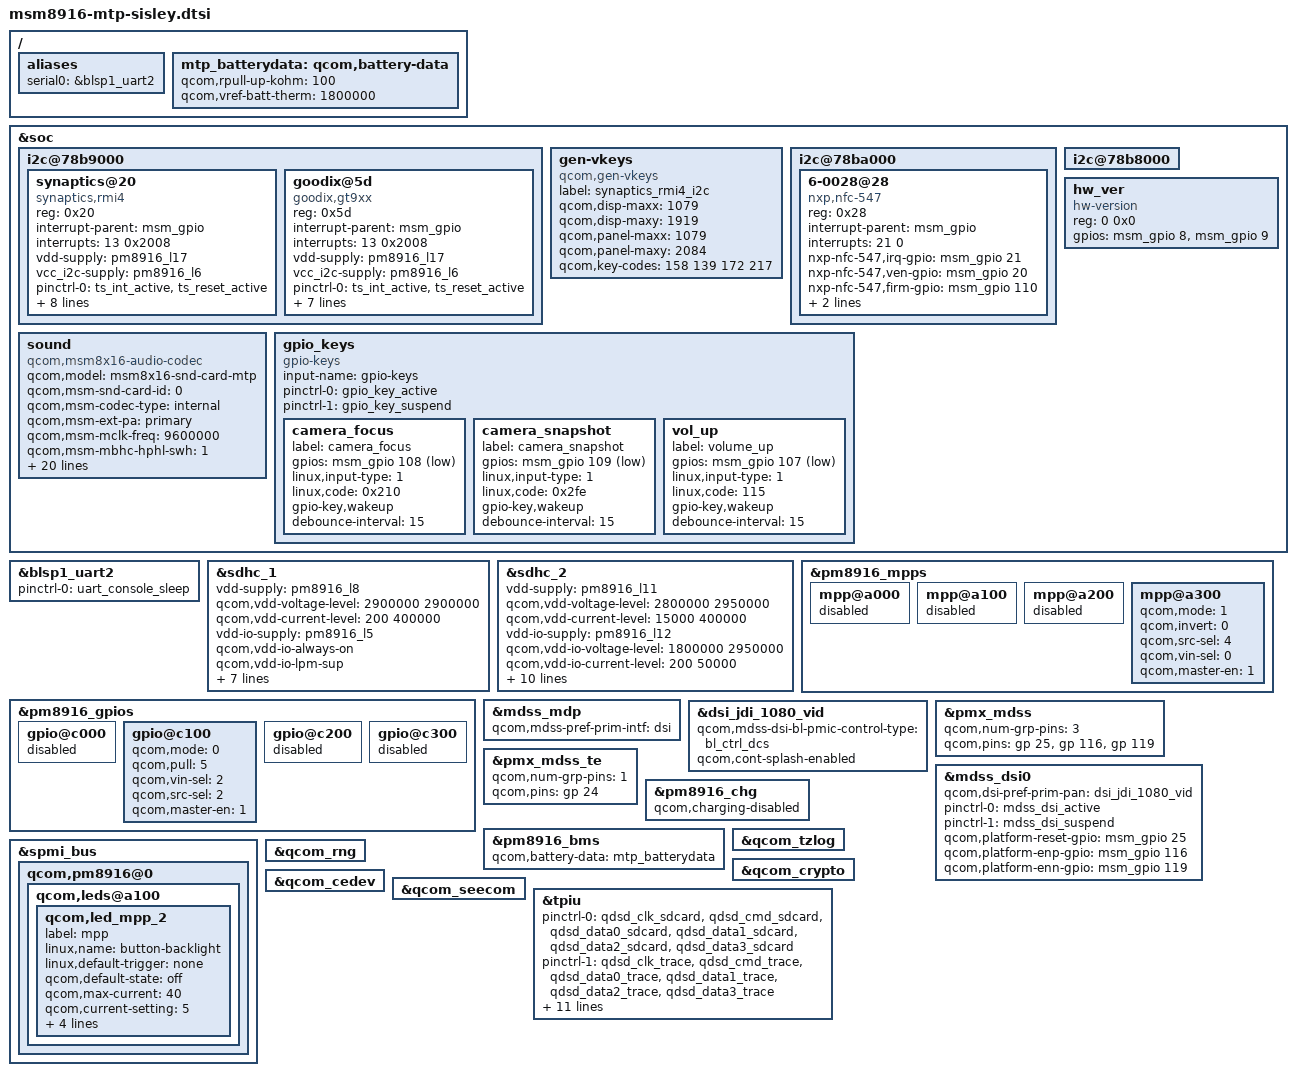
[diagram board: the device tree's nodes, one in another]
/* Copyright (c) 2014, The Linux Foundation. All rights reserved.
 *
 * This program is free software; you can redistribute it and/or modify
 * it under the terms of the GNU General Public License version 2 and
 * only version 2 as published by the Free Software Foundation.
 *
 * This program is distributed in the hope that it will be useful,
 * but WITHOUT ANY WARRANTY; without even the implied warranty of
 * MERCHANTABILITY or FITNESS FOR A PARTICULAR PURPOSE.  See the
 * GNU General Public License for more details.
 */

#include "msm8916.dtsi"
#include "msm8916-pinctrl.dtsi"
//chenglogn1 for sisley sub cam
#include "msm8916-camera-sensor-sisley.dtsi"//"msm8916-camera-sensor-mtp.dtsi"

/ {
	aliases {
		serial0 = &blsp1_uart2;
	};
};

&soc {
	i2c@78b9000 { /* BLSP1 QUP5 */
		synaptics@20 {
			compatible = "synaptics,rmi4";
			reg = <0x20>;
			interrupt-parent = <&msm_gpio>;
			interrupts = <13 0x2008>;
			vdd-supply = <&pm8916_l17>;
			vcc_i2c-supply = <&pm8916_l6>;
			/* pins used by touchscreen */
			pinctrl-names = "pmx_ts_active","pmx_ts_suspend";
			pinctrl-0 = <&ts_int_active &ts_reset_active>;
			pinctrl-1 = <&ts_int_suspend &ts_reset_suspend>;
			synaptics,irq-gpio = <&msm_gpio 13 0x2008>;
			synaptics,reset-gpio = <&msm_gpio 12 0x0>;
			synaptics,display-coords = <0 0 1079 1919>;
			synaptics,panel-coords = <0 0 1079 2084>;
			synaptics,i2c-pull-up;
			synaptics,power-down;
			synaptics,disable-gpios;
		};
		goodix@5d {
			compatible = "goodix,gt9xx";
			reg = <0x5d>;
			interrupt-parent = <&msm_gpio>;
			interrupts = <13 0x2008>;
			vdd-supply = <&pm8916_l17>;
			vcc_i2c-supply = <&pm8916_l6>;
			/* pins used by touchscreen */
			pinctrl-names = "pmx_ts_active","pmx_ts_suspend";
			pinctrl-0 = <&ts_int_active &ts_reset_active>;
			pinctrl-1 = <&ts_int_suspend &ts_reset_suspend>;
			goodix,reset-gpio = <&msm_gpio 12 0x0>;
			goodix,irq-gpio = <&msm_gpio 13 0x2008>;
			//goodix,ldo-en-gpio = <&msmgpio 15 0x00>;
			goodix,panel-coords = <0 0 720 1280>;
			goodix,display-coords = <0 0 720 1280>;
			goodix,button-map= <158 102 139>;
			goodix,family-id = <0x0>;
			/*
			goodix,cfg-data = [
		41 1C 02 C0 03 05 31 07 03 08
		14 08 41 32 03 04 00 00 00 00
		00 00 00 18 1A 1E 14 8B 2B 0C
		1C 1E 8C 20 00 00 00 9A 03 2D
		00 00 00 00 00 00 00 00 00 22
		00 4B FA 94 85 02 05 00 00 E5
		1B 1A ED 1C 1C 3C 1F 1E 3C 1F
		24 08 27 1F 00 00 10 38 58 00
		67 60 45 FF FF 07 00 00 00 00
		00 01 06 14 0C 16 E8 03 02 00
		00 03 28 28 E5 00 23 23 00 00
		00 00 02 04 06 08 0A 0C 0E 10
		12 14 16 18 FF FF FF FF FF FF
		FF FF FF FF FF FF FF FF FF FF
		FF FF 00 02 04 06 08 0A 0C 0F
		10 12 13 16 18 1C 1D 1E 1F 20
		21 22 24 26 FF FF FF FF FF FF
		FF FF FF FF FF FF FF FF FF FF
		FF FF FF FF 90 01];
		*/
		};
	};

	gen-vkeys {
		compatible = "qcom,gen-vkeys";
		label = "synaptics_rmi4_i2c";
		qcom,disp-maxx = <1079>;
		qcom,disp-maxy = <1919>;
		qcom,panel-maxx = <1079>;
		qcom,panel-maxy = <2084>;
		qcom,key-codes = <158 139 172 217>;
	};

	i2c@78ba000 { /* BLSP1 QUP6 */
		6-0028@28 {
			compatible = "nxp,nfc-547";
			reg = <0x28>;
          /*
			qcom,irq-gpio = <&msm_gpio 21 0x00>;
			qcom,dis-gpio = <&msm_gpio 20 0x00>;
			qcom,clk-src = "BBCLK2";
			qcom,clk-en-gpio = <&msm_gpio 0 0x00>;
          */
			interrupt-parent = <&msm_gpio>;
			interrupts = <21 0>;
          /*
			interrupt-names = "nfc_irq";
			pinctrl-names = "nfc_active","nfc_suspend";
			pinctrl-0 = <&nfc_int_active &nfc_disable_active>;
			pinctrl-1 = <&nfc_int_suspend &nfc_disable_suspend>;
			*/
			nxp-nfc-547,irq-gpio = <&msm_gpio 21 0x00>;
			nxp-nfc-547,ven-gpio = <&msm_gpio 20 0x00>;
			nxp-nfc-547,firm-gpio = <&msm_gpio 110 0x00>;
			qcom,clk-gpio = <&pm8916_gpios 2 0>;
			clocks = <&clock_rpm clk_bb_clk2_pin>;
			clock-names = "nfc_clk";
		};
	};

	i2c@78b8000 { /* BLSP1 QUP4 */

	};

	sound {
		compatible = "qcom,msm8x16-audio-codec";
		qcom,model = "msm8x16-snd-card-mtp";
		qcom,msm-snd-card-id = <0>;
		qcom,msm-codec-type = "internal";
		qcom,msm-ext-pa = "primary";
		qcom,msm-mclk-freq = <9600000>;
		qcom,msm-mbhc-hphl-swh = <1>;
		qcom,msm-mbhc-gnd-swh = <0>;
		/* lenovo-sw, lily8, 2014-09-11,for micbias-ext-cap-mode from QC patch,  begin*/
		qcom,msm-micbias1-ext-cap;
		/* lenovo-sw, lily8, 2014-09-11,for micbias-ext-cap-mode from QC patch,  end*/
		qcom,msm-hs-micbias-type = "internal";
		qcom,audio-routing =
			"RX_BIAS", "MCLK",
			"SPK_RX_BIAS", "MCLK",
			"INT_LDO_H", "MCLK",
			"MIC BIAS External", "Handset Mic",
			"MIC BIAS Internal2", "Headset Mic",
			"MIC BIAS External", "Secondary Mic",
			"AMIC1", "MIC BIAS External",
			"AMIC2", "MIC BIAS Internal2",
			"AMIC3", "MIC BIAS External";
		qcom,ext-spk-amp-gpio-1 = <&msm_gpio 97 0x0>;
		qcom,ext-spk-amp-gpio-2 = <&msm_gpio 98 0x0>;
		pinctrl-names = "cdc_lines_act",
				"cdc_lines_sus",
				"cdc_lines_sec_ext_act",
				"cdc_lines_sec_ext_sus",
				"cross_conn_det_act",
				"cross_conn_det_sus";
		pinctrl-0 = <&cdc_pdm_lines_act>;
		pinctrl-1 = <&cdc_pdm_lines_sus>;
		pinctrl-2 = <&cdc_pdm_lines_act &cdc_ext_pa_act
						&cdc_ext_pa_ws_act>;
		pinctrl-3 = <&cdc_pdm_lines_sus &cdc_ext_pa_sus
						&cdc_ext_pa_ws_sus>;
		pinctrl-4 = <&cross_conn_det_act>;
		pinctrl-5 = <&cross_conn_det_sus>;
	};
	/*lenovo-sw jixj 2014.6.9 add begin, for Z2 hardware id*/
	hw_ver {
		reg = <0 0x0>;
		compatible = "hw-version";
		gpios =
			<&msm_gpio 8 0>, /* VER_GPIO0 */
			<&msm_gpio 9 0>;   /* VER_GPIO1 */
	};
	/*lenovo-sw jixj 2014.6.9 add end*/
};

&blsp1_uart2 {
	status = "ok";
	pinctrl-names = "default";
	pinctrl-0 = <&uart_console_sleep>;
};

&soc {
	gpio_keys {
		compatible = "gpio-keys";
		input-name = "gpio-keys";
		pinctrl-names = "tlmm_gpio_key_active","tlmm_gpio_key_suspend";
		pinctrl-0 = <&gpio_key_active>;
		pinctrl-1 = <&gpio_key_suspend>;

		camera_focus {
			label = "camera_focus";
			gpios = <&msm_gpio 108 0x1>;
			linux,input-type = <1>;
			linux,code = <0x210>;
			gpio-key,wakeup;
			debounce-interval = <15>;
		};
		camera_snapshot {
			label = "camera_snapshot";
			gpios = <&msm_gpio 109 0x1>;
			linux,input-type = <1>;
			linux,code = <0x2fe>;
			gpio-key,wakeup;
			debounce-interval = <15>;
		};

		vol_up {
			label = "volume_up";
			gpios = <&msm_gpio 107 0x1>;
			linux,input-type = <1>;
			linux,code = <115>;
			gpio-key,wakeup;
			debounce-interval = <15>;
		};
	};
};

&sdhc_1 {
	vdd-supply = <&pm8916_l8>;
	qcom,vdd-voltage-level = <2900000 2900000>;
	qcom,vdd-current-level = <200 400000>;

	vdd-io-supply = <&pm8916_l5>;
	qcom,vdd-io-always-on;
	qcom,vdd-io-lpm-sup;
	qcom,vdd-io-voltage-level = <1800000 1800000>;
	qcom,vdd-io-current-level = <200 60000>;

	pinctrl-names = "active", "sleep";
	pinctrl-0 = <&sdc1_clk_on &sdc1_cmd_on &sdc1_data_on>;
	pinctrl-1 = <&sdc1_clk_off &sdc1_cmd_off &sdc1_data_off>;

	qcom,nonremovable;

	status = "ok";
};

&sdhc_2 {
	vdd-supply = <&pm8916_l11>;
	qcom,vdd-voltage-level = <2800000 2950000>;
	qcom,vdd-current-level = <15000 400000>;

	vdd-io-supply = <&pm8916_l12>;
	qcom,vdd-io-voltage-level = <1800000 2950000>;
	qcom,vdd-io-current-level = <200 50000>;

	pinctrl-names = "active", "sleep";
	pinctrl-0 = <&sdc2_clk_on &sdc2_cmd_on &sdc2_data_on &sdc2_cd_on>;
	pinctrl-1 = <&sdc2_clk_off &sdc2_cmd_off &sdc2_data_off &sdc2_cd_off>;

	#address-cells = <0>;
	interrupt-parent = <&sdhc_2>;
	interrupts = <0 1 2>;
	#interrupt-cells = <1>;
	interrupt-map-mask = <0xffffffff>;
	interrupt-map = <0 &intc 0 125 0
			1 &intc 0 221 0
			2 &msm_gpio 38 0>;
	interrupt-names = "hc_irq", "pwr_irq", "status_irq";
	cd-gpios = <&msm_gpio 38 0x1>;

	status = "ok";
};


&pm8916_mpps {
	mpp@a000 { /* MPP 1 */
		/* VDD_PX */
		status = "disabled";
	};

	mpp@a100 { /* MPP 2 */
		/* HR LED */
		status = "disabled";
	};

	mpp@a200 { /* MPP 3 */
		/* VREF DAC */
		status = "disabled";
	};

	mpp@a300 { /* MPP 4 */
		/* Backlight PWM */
		qcom,mode = <1>;		/* Digital output */
		qcom,invert = <0>;		/* Disable invert */
		qcom,src-sel = <4>;		/* DTEST1 */
		qcom,vin-sel = <0>;		/* VPH_PWR */
		qcom,master-en = <1>;		/* Enable MPP */
	};
};

&pm8916_gpios {
	gpio@c000 { /* GPIO 1 */
		/* Battery UICC Alarm */
		status = "disabled";
	};

	gpio@c100 { /* GPIO 2 */
		/* NFC_CLK_REQ */
		qcom,mode = <0>; /* QPNP_PIN_MODE_DIG_IN */
		qcom,pull = <5>; /* QPNP_PIN_PULL_NO */
		qcom,vin-sel = <2>; /* QPNP_PIN_VIN2 */
		qcom,src-sel = <2>; /* QPNP_PIN_SEL_FUNC_1 */
		qcom,master-en = <1>;
	};

	gpio@c200 { /* GPIO 3 */
		/* External regulator control for WTR */
		status = "disabled";
	};

	gpio@c300 { /* GPIO 4 */
		/* External regulator control for APC */
		status = "disabled";
	};
};

#include "lenovo-dsi-panel-hx8389b-tianma-qhd-video.dtsi"
/*#include "dsi-panel-jdi-1080p-video.dtsi"*/

&mdss_mdp {
	qcom,mdss-pref-prim-intf = "dsi";
};

&dsi_jdi_1080_vid {
	qcom,mdss-dsi-bl-pmic-control-type = "bl_ctrl_dcs";
/*
	qcom,mdss-dsi-bl-pmic-pwm-frequency = <100>;
	qcom,mdss-dsi-bl-pmic-bank-select = <0>;
	qcom,mdss-dsi-pwm-gpio = <&pm8916_mpps 4 0>;
*/
};

&pmx_mdss {
	qcom,num-grp-pins = <3>;
	qcom,pins = <&gp 25>, <&gp 116>, <&gp 119>;
};

&pmx_mdss_te {
	qcom,num-grp-pins = <1>;
	qcom,pins = <&gp 24>;
};

&mdss_dsi0 {
       qcom,dsi-pref-prim-pan = <&dsi_jdi_1080_vid>;
       pinctrl-names = "mdss_default", "mdss_sleep";
       pinctrl-0 = <&mdss_dsi_active>;
       pinctrl-1 = <&mdss_dsi_suspend>;

	/*qcom,platform-enable-gpio = <&msm_gpio 97 0>;*/
	qcom,platform-reset-gpio = <&msm_gpio 25 0>;
	qcom,platform-enp-gpio = <&msm_gpio 116 0>;
        qcom,platform-enn-gpio = <&msm_gpio 119 0>;
	/*qcom,platform-bklight-en-gpio = <&msm_gpio 98 0>;*/
};

&dsi_jdi_1080_vid {
       qcom,cont-splash-enabled;
};
/*
&dsi_gl_qhp_vid {
       qcom,cont-splash-enabled;
};
*/

&pm8916_chg {
	status = "ok";
	qcom,charging-disabled;
};

/ {
	mtp_batterydata: qcom,battery-data {
		qcom,rpull-up-kohm = <100>;
		qcom,vref-batt-therm = <1800000>;

		#include "batterydata-palladium.dtsi"
	};
};

&pm8916_bms {
	status = "ok";
	qcom,battery-data = <&mtp_batterydata>;
};

&spmi_bus {
	qcom,pm8916@0 {
		qcom,leds@a100 {
			status = "okay";
			qcom,led_mpp_2 {
				label = "mpp";
				linux,name = "button-backlight";
				linux,default-trigger = "none";
				qcom,default-state = "off";
				qcom,max-current = <40>;
				qcom,current-setting = <5>;
				qcom,id = <6>;
				qcom,mode = "manual";
				qcom,source-sel = <1>;
				qcom,mode-ctrl = <0x60>;
			};
		};
	};
};

&qcom_tzlog {
	status = "okay";
};

&qcom_rng {
	status = "okay";
};

&qcom_crypto {
	status = "okay";
};

&qcom_cedev {
	status = "okay";
};

&qcom_seecom {
	status = "okay";
};

/* CoreSight */
&tpiu {
      pinctrl-names = "sdcard", "trace", "swduart",
		      "swdtrc", "jtag", "spmi";
       /* NIDnT */
      pinctrl-0 = <&qdsd_clk_sdcard &qdsd_cmd_sdcard
                  &qdsd_data0_sdcard &qdsd_data1_sdcard
                  &qdsd_data2_sdcard &qdsd_data3_sdcard>;
      pinctrl-1 = <&qdsd_clk_trace &qdsd_cmd_trace
                  &qdsd_data0_trace &qdsd_data1_trace
                  &qdsd_data2_trace &qdsd_data3_trace>;
      pinctrl-2 = <&qdsd_cmd_swduart &qdsd_data0_swduart
                  &qdsd_data1_swduart &qdsd_data2_swduart
                  &qdsd_data3_swduart>;
      pinctrl-4 = <&qdsd_clk_swdtrc &qdsd_cmd_swdtrc
                  &qdsd_data0_swdtrc &qdsd_data1_swdtrc
                  &qdsd_data2_swdtrc &qdsd_data3_swdtrc>;
      pinctrl-5 = <&qdsd_cmd_jtag &qdsd_data0_jtag
                  &qdsd_data1_jtag &qdsd_data2_jtag
                  &qdsd_data3_jtag>;
      pinctrl-6 = <&qdsd_clk_spmi &qdsd_cmd_spmi
                  &qdsd_data0_spmi &qdsd_data3_spmi>;
};
